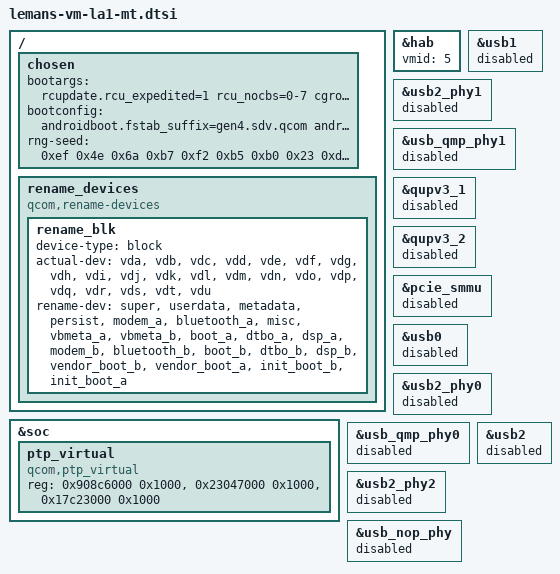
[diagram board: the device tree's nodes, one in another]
// SPDX-License-Identifier: BSD-3-Clause
/*
 * Copyright (c) Qualcomm Technologies, Inc. and/or its subsidiaries.
 */

&soc {
	ptp_virtual {
		compatible = "qcom,ptp_virtual";
		reg = <0x908c6000 0x1000>,
			<0x23047000 0x1000>,
			<0x17c23000 0x1000>;
		reg-names = "ptp_carveout_mem",
				"ptp_reg",
				"qtimer_reg";
	};
};


&hab {
	vmid = <5>;
};

/ {
	chosen {
		bootargs = "rcupdate.rcu_expedited=1 rcu_nocbs=0-7 cgroup.memory=nokmem,nosocket kpti=0 ufshcd-core.use_mcq_mode=n arm64.nopauth kasan=off msm_show_resume_irq.debug_mask=1";
		bootconfig = "androidboot.fstab_suffix=gen4.sdv.qcom androidboot.dtbo_idx=4";
		rng-seed = <0xef 0x4e 0x6a 0xb7 0xf2 0xb5 0xb0 0x23 0xdf 0xa7 0xeb 0x2b 0x44 0x40 0x11 0x7d 0x5c 0xbb 0xf1 0x21 0x5d 0x82 0x1a 0x4a 0x04 0xf5 0x93 0x8a 0x7f 0x2a 0xee 0x56>;
	};

	rename_devices: rename_devices {
		compatible = "qcom,rename-devices";
		rename_blk: rename_blk {
			device-type = "block";
			actual-dev = "vda", "vdb", "vdc",
					"vdd", "vde", "vdf",
					"vdg", "vdh", "vdi",
					"vdj", "vdk", "vdl",
					"vdm", "vdn", "vdo",
					"vdp", "vdq", "vdr",
					"vds", "vdt", "vdu";
			rename-dev = "super", "userdata", "metadata",
					"persist", "modem_a","bluetooth_a",
					"misc", "vbmeta_a", "vbmeta_b",
					"boot_a", "dtbo_a", "dsp_a",
					"modem_b", "bluetooth_b", "boot_b",
					"dtbo_b", "dsp_b", "vendor_boot_b",
					"vendor_boot_a", "init_boot_b", "init_boot_a";
		};
	};
};

&usb1 {
	/delete-property/ qcom,host-poweroff-in-pm-suspend;
	/delete-property/ qcom,default-mode-host;
	status = "disabled";
};

&usb2_phy1 {
	status = "disabled";
};

&usb_qmp_phy1 {
	status = "disabled";
};

&qupv3_1 {
	status = "disabled";
};

&qupv3_2 {
	status = "disabled";
};

&pcie_smmu {
	status = "disabled";
};

&usb0 {
	status = "disabled";
};

&usb2_phy0 {
	status = "disabled";
};

&usb_qmp_phy0 {
	status = "disabled";
};

&usb2 {
	status = "disabled";
};

&usb2_phy2 {
	status = "disabled";
};

&usb_nop_phy {
	status = "disabled";
};
